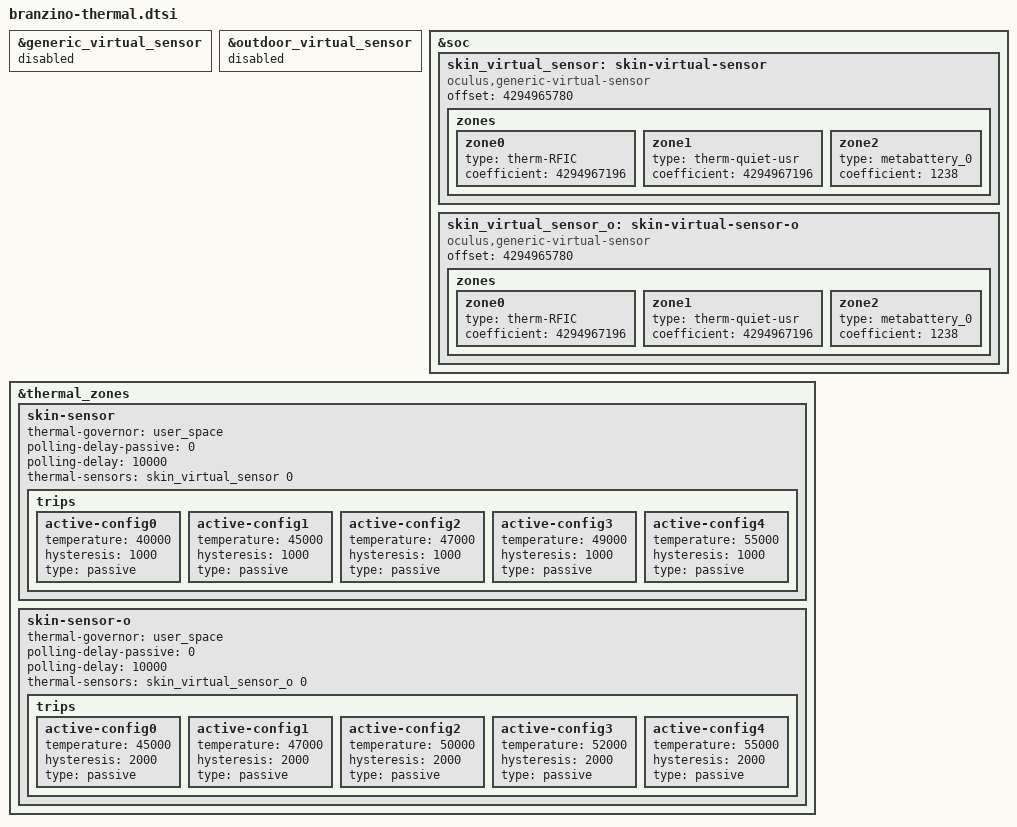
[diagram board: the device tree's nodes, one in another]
&generic_virtual_sensor {
        status = "disabled";
};

&outdoor_virtual_sensor {
	status = "disabled";
};

&soc {
	skin_virtual_sensor: skin-virtual-sensor {
		compatible = "oculus,generic-virtual-sensor";
		#thermal-sensor-cells = <0>;
		status = "ok";
		// 32 bit 2's complement -1516
		offset = <4294965780>;
		zones {
			zone0 {
				type = "therm-RFIC";
				// 32 bit 2's complement -100
				coefficient = <4294967196>;
			};
			zone1 {
				type = "therm-quiet-usr";
				// 32 bit 2's complement -100
				coefficient = <4294967196>;
			};
			zone2 {
				type = "metabattery_0";
				coefficient = <1238>;
			};
		};
	};
	skin_virtual_sensor_o: skin-virtual-sensor-o {
		compatible = "oculus,generic-virtual-sensor";
		#thermal-sensor-cells = <0>;
		status = "ok";
		// 32 bit 2's complement -1516
		offset = <4294965780>;
		zones {
			zone0 {
				type = "therm-RFIC";
				// 32 bit 2's complement -100
				coefficient = <4294967196>;
			};
			zone1 {
				type = "therm-quiet-usr";
				// 32 bit 2's complement -100
				coefficient = <4294967196>;
			};
			zone2 {
				type = "metabattery_0";
				coefficient = <1238>;
			};
		};
	};

};

&thermal_zones {
	skin-sensor {
		thermal-governor = "user_space";
		polling-delay-passive = <0>;
		polling-delay = <10000>;
		thermal-sensors = <&skin_virtual_sensor 0>;
		trips {
			active-config0 {
				temperature = <40000>;
				hysteresis = <1000>;
				type = "passive";
			};
			active-config1 {
				temperature = <45000>;
				hysteresis = <1000>;
				type = "passive";
			};
			active-config2 {
				temperature = <47000>;
				hysteresis = <1000>;
				type = "passive";
			};
			active-config3 {
				temperature = <49000>;
				hysteresis = <1000>;
				type = "passive";
			};
			active-config4 {
				temperature = <55000>;
				hysteresis = <1000>;
				type = "passive";
			};
		};
	};
	skin-sensor-o {
		thermal-governor = "user_space";
		polling-delay-passive = <0>;
		polling-delay = <10000>;
		thermal-sensors = <&skin_virtual_sensor_o 0>;
		trips {
			active-config0 {
				temperature = <45000>;
				hysteresis = <2000>;
				type = "passive";
			};
			active-config1 {
				temperature = <47000>;
				hysteresis = <2000>;
				type = "passive";
			};
			active-config2 {
				temperature = <50000>;
				hysteresis = <2000>;
				type = "passive";
			};
			active-config3 {
				temperature = <52000>;
				hysteresis = <2000>;
				type = "passive";
			};
			active-config4 {
				temperature = <55000>;
				hysteresis = <2000>;
				type = "passive";
			};
		};
	};
};
